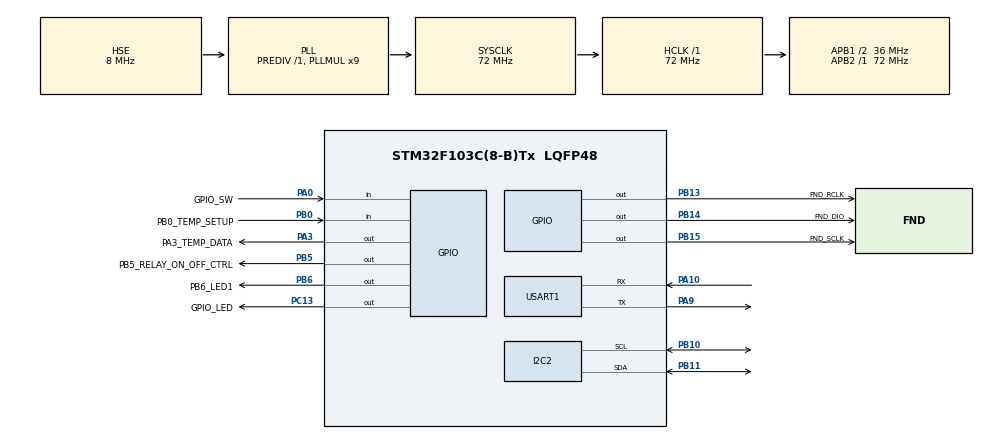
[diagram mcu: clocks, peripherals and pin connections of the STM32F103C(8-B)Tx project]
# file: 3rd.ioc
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Mcu.Family=STM32F1
Mcu.Name=STM32F103C(8-B)Tx
Mcu.Package=LQFP48
NVIC.PriorityGroup=NVIC_PRIORITYGROUP_4
NVIC.TIM2_IRQn=true\:0\:0\:false\:false\:true\:true\:true\:true
NVIC.TIM3_IRQn=true\:10\:0\:true\:false\:true\:true\:true\:true
PA0-WKUP.GPIO_Label=GPIO_SW
PA0-WKUP.GPIO_PuPd=GPIO_PULLUP
PA0-WKUP.Signal=GPIO_Input
PA10.Mode=Asynchronous
PA10.Signal=USART1_RX
PA13.Mode=Serial_Wire
PA13.Signal=SYS_JTMS-SWDIO
PA14.Mode=Serial_Wire
PA14.Signal=SYS_JTCK-SWCLK
PA3.GPIO_Label=PA3_TEMP_DATA
PA3.GPIO_PuPd=GPIO_PULLUP
PA3.GPIO_Speed=GPIO_SPEED_FREQ_HIGH
PA3.PinState=GPIO_PIN_SET
PA3.Signal=GPIO_Output
PA9.Mode=Asynchronous
PA9.Signal=USART1_TX
PB0.GPIO_Label=PB0_TEMP_SETUP
PB0.GPIO_PuPd=GPIO_PULLUP
PB0.Signal=GPIO_Input
PB10.Mode=I2C
PB10.Signal=I2C2_SCL
PB11.Mode=I2C
PB11.Signal=I2C2_SDA
PB13.GPIO_Label=FND_RCLK
PB13.GPIO_ModeDefaultOutputPP=GPIO_MODE_OUTPUT_PP
PB13.GPIO_PuPd=GPIO_PULLUP
PB13.GPIO_Speed=GPIO_SPEED_FREQ_HIGH
PB13.PinState=GPIO_PIN_SET
PB13.Signal=GPIO_Output
PB14.GPIO_Label=FND_DIO
PB14.GPIO_ModeDefaultOutputPP=GPIO_MODE_OUTPUT_PP
PB14.GPIO_PuPd=GPIO_PULLUP
PB14.GPIO_Speed=GPIO_SPEED_FREQ_HIGH
PB14.PinState=GPIO_PIN_SET
PB14.Signal=GPIO_Output
PB15.GPIO_Label=FND_SCLK
PB15.GPIO_ModeDefaultOutputPP=GPIO_MODE_OUTPUT_PP
PB15.GPIO_PuPd=GPIO_PULLUP
PB15.GPIO_Speed=GPIO_SPEED_FREQ_HIGH
PB15.PinState=GPIO_PIN_SET
PB15.Signal=GPIO_Output
PB5.GPIO_Label=PB5_RELAY_ON_OFF_CTRL
PB5.GPIO_PuPd=GPIO_PULLDOWN
PB5.GPIO_Speed=GPIO_SPEED_FREQ_HIGH
PB5.PinState=GPIO_PIN_RESET
PB5.Signal=GPIO_Output
PB6.GPIO_Label=PB6_LED1
PB6.GPIO_PuPd=GPIO_PULLUP
PB6.PinState=GPIO_PIN_SET
PB6.Signal=GPIO_Output
PC13-TAMPER-RTC.GPIO_Label=GPIO_LED
PC13-TAMPER-RTC.GPIO_ModeDefaultOutputPP=GPIO_MODE_OUTPUT_PP
PC13-TAMPER-RTC.GPIO_PuPd=GPIO_PULLDOWN
PC13-TAMPER-RTC.GPIO_Speed=GPIO_SPEED_FREQ_HIGH
PC13-TAMPER-RTC.PinState=GPIO_PIN_SET
PC13-TAMPER-RTC.Signal=GPIO_Output
PC14-OSC32_IN.Mode=LSE-External-Oscillator
PC14-OSC32_IN.Signal=RCC_OSC32_IN
PC15-OSC32_OUT.Mode=LSE-External-Oscillator
PC15-OSC32_OUT.Signal=RCC_OSC32_OUT
PD0-OSC_IN.Mode=HSE-External-Oscillator
PD0-OSC_IN.Signal=RCC_OSC_IN
PD1-OSC_OUT.Mode=HSE-External-Oscillator
PD1-OSC_OUT.Signal=RCC_OSC_OUT
ProjectManager.HeapSize=0x200
ProjectManager.StackSize=0x400
ProjectManager.TargetToolchain=STM32CubeIDE
RCC.AHBFreq_Value=72000000
RCC.APB1CLKDivider=RCC_HCLK_DIV2
RCC.APB1Freq_Value=36000000
RCC.APB1TimFreq_Value=72000000
RCC.APB2Freq_Value=72000000
RCC.APB2TimFreq_Value=72000000
RCC.HCLKFreq_Value=72000000
RCC.PLLMUL=RCC_PLL_MUL9
RCC.PLLSourceVirtual=RCC_PLLSOURCE_HSE
RCC.SYSCLKFreq_VALUE=72000000
RCC.SYSCLKSource=RCC_SYSCLKSOURCE_PLLCLK
RCC.USBFreq_Value=72000000
TIM2.AutoReloadPreload=TIM_AUTORELOAD_PRELOAD_DISABLE
TIM2.Period=65535
TIM2.Prescaler=(72-1)
TIM3.Period=49
TIM3.Prescaler=71
USART1.VirtualMode=VM_ASYNC
VP_TIM2_VS_ClockSourceINT.Mode=Internal
VP_TIM3_VS_ClockSourceINT.Mode=Internal
board=custom

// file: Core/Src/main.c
/* USER CODE BEGIN Header */
/**
  ******************************************************************************
  * @file           : main.c
  * @brief          : Main program body
  ******************************************************************************
  * @attention
  *
  * Copyright (c) 2024 STMicroelectronics.
  * All rights reserved.
  *
  * This software is licensed under terms that can be found in the LICENSE file
  * in the root directory of this software component.
  * If no LICENSE file comes with this software, it is provided AS-IS.
  *
  ******************************************************************************
  */
/* USER CODE END Header */
#include "main.h"

/* USER CODE BEGIN Includes */
#include "FND_Controller.h"
#include "onewire.h"
#include "ds18b20.h"
#include "heaterController.h"

#include "fonts.h"
#include "ssd1306.h"
#include "test.h"
#include "bitmap.h"
#include "horse_anim.h"
/* USER CODE END Includes */

I2C_HandleTypeDef hi2c2;

TIM_HandleTypeDef htim2;
TIM_HandleTypeDef htim3;

UART_HandleTypeDef huart1;

void SystemClock_Config(void);
static void MX_GPIO_Init(void);
static void MX_USART1_UART_Init(void);
static void MX_TIM2_Init(void);
static void MX_TIM3_Init(void);
static void MX_I2C2_Init(void);

int main(void)
{

  /* MCU Configuration--------------------------------------------------------*/

  /* Reset of all peripherals, Initializes the Flash interface and the Systick. */
  HAL_Init();

  /* Configure the system clock */
  SystemClock_Config();

  /* Initialize all configured peripherals */
  MX_GPIO_Init();
  MX_USART1_UART_Init();
  MX_TIM2_Init();
  MX_TIM3_Init();
  MX_I2C2_Init();
  /* USER CODE BEGIN 2 */

HAL_TIM_Base_Start_IT(&htim3);//timer interrupt
Ds18b20_Init_simple();
  /* USER CODE END 2 */

  /* Infinite loop */
  /* USER CODE BEGIN WHILE */

  while (1)
  {
	  /*if(!isConverting()){
		  StartConverting();
	  }

	  	  checkConverting();

	  if(!isConverting()){
	  	  temper = getTemper();
	  	}*/

    /* USER CODE END WHILE */

  }
}

void SystemClock_Config(void)
{
  RCC_OscInitTypeDef RCC_OscInitStruct = {0};
  RCC_ClkInitTypeDef RCC_ClkInitStruct = {0};

  /** Initializes the RCC Oscillators according to the specified parameters
  * in the RCC_OscInitTypeDef structure.
  */
  RCC_OscInitStruct.OscillatorType = RCC_OSCILLATORTYPE_HSE;
  RCC_OscInitStruct.HSEState = RCC_HSE_ON;
  RCC_OscInitStruct.HSEPredivValue = RCC_HSE_PREDIV_DIV1;
  RCC_OscInitStruct.HSIState = RCC_HSI_ON;
  RCC_OscInitStruct.PLL.PLLState = RCC_PLL_ON;
  RCC_OscInitStruct.PLL.PLLSource = RCC_PLLSOURCE_HSE;
  RCC_OscInitStruct.PLL.PLLMUL = RCC_PLL_MUL9;
  if (HAL_RCC_OscConfig(&RCC_OscInitStruct) != HAL_OK)
  {
    Error_Handler();
  }

  /** Initializes the CPU, AHB and APB buses clocks
  */
  RCC_ClkInitStruct.ClockType = RCC_CLOCKTYPE_HCLK|RCC_CLOCKTYPE_SYSCLK
                              |RCC_CLOCKTYPE_PCLK1|RCC_CLOCKTYPE_PCLK2;
  RCC_ClkInitStruct.SYSCLKSource = RCC_SYSCLKSOURCE_PLLCLK;
  RCC_ClkInitStruct.AHBCLKDivider = RCC_SYSCLK_DIV1;
  RCC_ClkInitStruct.APB1CLKDivider = RCC_HCLK_DIV2;
  RCC_ClkInitStruct.APB2CLKDivider = RCC_HCLK_DIV1;

  if (HAL_RCC_ClockConfig(&RCC_ClkInitStruct, FLASH_LATENCY_2) != HAL_OK)
  {
    Error_Handler();
  }
}

static void MX_I2C2_Init(void)
{

  hi2c2.Instance = I2C2;
  hi2c2.Init.ClockSpeed = 100000;
  hi2c2.Init.DutyCycle = I2C_DUTYCYCLE_2;
  hi2c2.Init.OwnAddress1 = 0;
  hi2c2.Init.AddressingMode = I2C_ADDRESSINGMODE_7BIT;
  hi2c2.Init.DualAddressMode = I2C_DUALADDRESS_DISABLE;
  hi2c2.Init.OwnAddress2 = 0;
  hi2c2.Init.GeneralCallMode = I2C_GENERALCALL_DISABLE;
  hi2c2.Init.NoStretchMode = I2C_NOSTRETCH_DISABLE;
  if (HAL_I2C_Init(&hi2c2) != HAL_OK)
  {
    Error_Handler();
  }

}

static void MX_TIM2_Init(void)
{

  TIM_ClockConfigTypeDef sClockSourceConfig = {0};
  TIM_MasterConfigTypeDef sMasterConfig = {0};

  htim2.Instance = TIM2;
  htim2.Init.Prescaler = (72-1);
  htim2.Init.CounterMode = TIM_COUNTERMODE_UP;
  htim2.Init.Period = 65535;
  htim2.Init.ClockDivision = TIM_CLOCKDIVISION_DIV1;
  htim2.Init.AutoReloadPreload = TIM_AUTORELOAD_PRELOAD_DISABLE;
  if (HAL_TIM_Base_Init(&htim2) != HAL_OK)
  {
    Error_Handler();
  }
  sClockSourceConfig.ClockSource = TIM_CLOCKSOURCE_INTERNAL;
  if (HAL_TIM_ConfigClockSource(&htim2, &sClockSourceConfig) != HAL_OK)
  {
    Error_Handler();
  }
  sMasterConfig.MasterOutputTrigger = TIM_TRGO_RESET;
  sMasterConfig.MasterSlaveMode = TIM_MASTERSLAVEMODE_DISABLE;
  if (HAL_TIMEx_MasterConfigSynchronization(&htim2, &sMasterConfig) != HAL_OK)
  {
    Error_Handler();
  }

}

static void MX_TIM3_Init(void)
{

  TIM_ClockConfigTypeDef sClockSourceConfig = {0};
  TIM_MasterConfigTypeDef sMasterConfig = {0};

  htim3.Instance = TIM3;
  htim3.Init.Prescaler = 71;
  htim3.Init.CounterMode = TIM_COUNTERMODE_UP;
  htim3.Init.Period = 49;
  htim3.Init.ClockDivision = TIM_CLOCKDIVISION_DIV1;
  htim3.Init.AutoReloadPreload = TIM_AUTORELOAD_PRELOAD_DISABLE;
  if (HAL_TIM_Base_Init(&htim3) != HAL_OK)
  {
    Error_Handler();
  }
  sClockSourceConfig.ClockSource = TIM_CLOCKSOURCE_INTERNAL;
  if (HAL_TIM_ConfigClockSource(&htim3, &sClockSourceConfig) != HAL_OK)
  {
    Error_Handler();
  }
  sMasterConfig.MasterOutputTrigger = TIM_TRGO_RESET;
  sMasterConfig.MasterSlaveMode = TIM_MASTERSLAVEMODE_DISABLE;
  if (HAL_TIMEx_MasterConfigSynchronization(&htim3, &sMasterConfig) != HAL_OK)
  {
    Error_Handler();
  }

}

static void MX_USART1_UART_Init(void)
{

  huart1.Instance = USART1;
  huart1.Init.BaudRate = 115200;
  huart1.Init.WordLength = UART_WORDLENGTH_8B;
  huart1.Init.StopBits = UART_STOPBITS_1;
  huart1.Init.Parity = UART_PARITY_NONE;
  huart1.Init.Mode = UART_MODE_TX_RX;
  huart1.Init.HwFlowCtl = UART_HWCONTROL_NONE;
  huart1.Init.OverSampling = UART_OVERSAMPLING_16;
  if (HAL_UART_Init(&huart1) != HAL_OK)
  {
    Error_Handler();
  }

}

static void MX_GPIO_Init(void)
{
  GPIO_InitTypeDef GPIO_InitStruct = {0};

  /* GPIO Ports Clock Enable */
  __HAL_RCC_GPIOC_CLK_ENABLE();
  __HAL_RCC_GPIOD_CLK_ENABLE();
  __HAL_RCC_GPIOA_CLK_ENABLE();
  __HAL_RCC_GPIOB_CLK_ENABLE();

  /*Configure GPIO pin Output Level */
  HAL_GPIO_WritePin(GPIO_LED_GPIO_Port, GPIO_LED_Pin, GPIO_PIN_SET);

  /*Configure GPIO pin Output Level */
  HAL_GPIO_WritePin(PA3_TEMP_DATA_GPIO_Port, PA3_TEMP_DATA_Pin, GPIO_PIN_SET);

  /*Configure GPIO pin Output Level */
  HAL_GPIO_WritePin(GPIOB, FND_RCLK_Pin|FND_DIO_Pin|FND_SCLK_Pin|PB6_LED1_Pin, GPIO_PIN_SET);

  /*Configure GPIO pin Output Level */
  HAL_GPIO_WritePin(PB5_RELAY_ON_OFF_CTRL_GPIO_Port, PB5_RELAY_ON_OFF_CTRL_Pin, GPIO_PIN_RESET);

  /*Configure GPIO pin : GPIO_LED_Pin */
  GPIO_InitStruct.Pin = GPIO_LED_Pin;
  GPIO_InitStruct.Mode = GPIO_MODE_OUTPUT_PP;
  GPIO_InitStruct.Pull = GPIO_PULLDOWN;
  GPIO_InitStruct.Speed = GPIO_SPEED_FREQ_HIGH;
  HAL_GPIO_Init(GPIO_LED_GPIO_Port, &GPIO_InitStruct);

  /*Configure GPIO pin : GPIO_SW_Pin */
  GPIO_InitStruct.Pin = GPIO_SW_Pin;
  GPIO_InitStruct.Mode = GPIO_MODE_INPUT;
  GPIO_InitStruct.Pull = GPIO_PULLUP;
  HAL_GPIO_Init(GPIO_SW_GPIO_Port, &GPIO_InitStruct);

  /*Configure GPIO pin : PA3_TEMP_DATA_Pin */
  GPIO_InitStruct.Pin = PA3_TEMP_DATA_Pin;
  GPIO_InitStruct.Mode = GPIO_MODE_OUTPUT_PP;
  GPIO_InitStruct.Pull = GPIO_PULLUP;
  GPIO_InitStruct.Speed = GPIO_SPEED_FREQ_HIGH;
  HAL_GPIO_Init(PA3_TEMP_DATA_GPIO_Port, &GPIO_InitStruct);

  /*Configure GPIO pin : PB0_TEMP_SETUP_Pin */
  GPIO_InitStruct.Pin = PB0_TEMP_SETUP_Pin;
  GPIO_InitStruct.Mode = GPIO_MODE_INPUT;
  GPIO_InitStruct.Pull = GPIO_PULLUP;
  HAL_GPIO_Init(PB0_TEMP_SETUP_GPIO_Port, &GPIO_InitStruct);

  /*Configure GPIO pins : FND_RCLK_Pin FND_DIO_Pin FND_SCLK_Pin */
  GPIO_InitStruct.Pin = FND_RCLK_Pin|FND_DIO_Pin|FND_SCLK_Pin;
  GPIO_InitStruct.Mode = GPIO_MODE_OUTPUT_PP;
  GPIO_InitStruct.Pull = GPIO_PULLUP;
  GPIO_InitStruct.Speed = GPIO_SPEED_FREQ_HIGH;
  HAL_GPIO_Init(GPIOB, &GPIO_InitStruct);

  /*Configure GPIO pin : PB5_RELAY_ON_OFF_CTRL_Pin */
  GPIO_InitStruct.Pin = PB5_RELAY_ON_OFF_CTRL_Pin;
  GPIO_InitStruct.Mode = GPIO_MODE_OUTPUT_PP;
  GPIO_InitStruct.Pull = GPIO_PULLDOWN;
  GPIO_InitStruct.Speed = GPIO_SPEED_FREQ_HIGH;
  HAL_GPIO_Init(PB5_RELAY_ON_OFF_CTRL_GPIO_Port, &GPIO_InitStruct);

  /*Configure GPIO pin : PB6_LED1_Pin */
  GPIO_InitStruct.Pin = PB6_LED1_Pin;
  GPIO_InitStruct.Mode = GPIO_MODE_OUTPUT_PP;
  GPIO_InitStruct.Pull = GPIO_PULLUP;
  GPIO_InitStruct.Speed = GPIO_SPEED_FREQ_LOW;
  HAL_GPIO_Init(PB6_LED1_GPIO_Port, &GPIO_InitStruct);

}

void Error_Handler(void)
{
  __disable_irq();
  while (1)
  {
  }
}
